AUTOSAR XML (schema 00050)
package /FCASWCs/OnBdDevAb/BufCrk
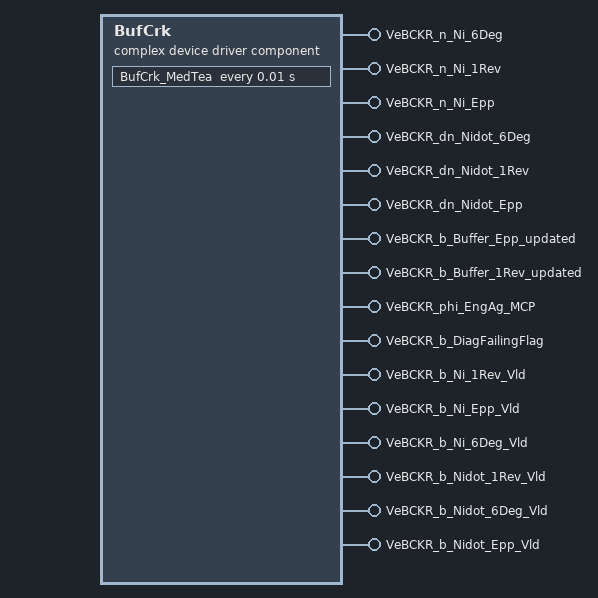
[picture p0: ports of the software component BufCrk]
  complex device driver sw component type BufCrk
    16 x provide port:
      VeBCKR_n_Ni_6Deg: nonqueued-sender-com-spec{data-element=VeBCKR_n_Ni_6Deg, init-value=0}, provided-interface=VeBCKR_n_Ni_6Deg
      VeBCKR_n_Ni_1Rev: nonqueued-sender-com-spec{data-element=VeBCKR_n_Ni_1Rev, init-value=0}, provided-interface=VeBCKR_n_Ni_1Rev
      VeBCKR_n_Ni_Epp: nonqueued-sender-com-spec{data-element=VeBCKR_n_Ni_Epp, init-value=0}, provided-interface=VeBCKR_n_Ni_Epp
      VeBCKR_dn_Nidot_6Deg: nonqueued-sender-com-spec{data-element=VeBCKR_dn_Nidot_6Deg, init-value=0}, provided-interface=VeBCKR_dn_Nidot_6Deg
      VeBCKR_dn_Nidot_1Rev: nonqueued-sender-com-spec{data-element=VeBCKR_dn_Nidot_1Rev, init-value=0}, provided-interface=VeBCKR_dn_Nidot_1Rev
      VeBCKR_dn_Nidot_Epp: nonqueued-sender-com-spec{data-element=VeBCKR_dn_Nidot_Epp, init-value=0}, provided-interface=VeBCKR_dn_Nidot_Epp
      VeBCKR_b_Buffer_Epp_updated: nonqueued-sender-com-spec{data-element=VeBCKR_b_Buffer_Epp_updated, init-value=0}, provided-interface=VeBCKR_b_Buffer_Epp_updated
      VeBCKR_b_Buffer_1Rev_updated: nonqueued-sender-com-spec{data-element=VeBCKR_b_Buffer_1Rev_updated, init-value=0}, provided-interface=VeBCKR_b_Buffer_1Rev_updated
      VeBCKR_phi_EngAg_MCP: nonqueued-sender-com-spec{data-element=VeBCKR_phi_EngAg_MCP, init-value=0}, provided-interface=VeBCKR_phi_EngAg_MCP
      VeBCKR_b_DiagFailingFlag: nonqueued-sender-com-spec{data-element=VeBCKR_b_DiagFailingFlag, init-value=0}, provided-interface=VeBCKR_b_DiagFailingFlag
      VeBCKR_b_Ni_1Rev_Vld: nonqueued-sender-com-spec{data-element=VeBCKR_b_Ni_1Rev_Vld, init-value=0}, provided-interface=VeBCKR_b_Ni_1Rev_Vld
      VeBCKR_b_Ni_Epp_Vld: nonqueued-sender-com-spec{data-element=VeBCKR_b_Ni_Epp_Vld, init-value=0}, provided-interface=VeBCKR_b_Ni_Epp_Vld
      VeBCKR_b_Ni_6Deg_Vld: nonqueued-sender-com-spec{data-element=VeBCKR_b_Ni_6Deg_Vld, init-value=0}, provided-interface=VeBCKR_b_Ni_6Deg_Vld
      VeBCKR_b_Nidot_1Rev_Vld: nonqueued-sender-com-spec{data-element=VeBCKR_b_Nidot_1Rev_Vld, init-value=0}, provided-interface=VeBCKR_b_Nidot_1Rev_Vld
      VeBCKR_b_Nidot_6Deg_Vld: nonqueued-sender-com-spec{data-element=VeBCKR_b_Nidot_6Deg_Vld, init-value=0}, provided-interface=VeBCKR_b_Nidot_6Deg_Vld
      VeBCKR_b_Nidot_Epp_Vld: nonqueued-sender-com-spec{data-element=VeBCKR_b_Nidot_Epp_Vld, init-value=0}, provided-interface=VeBCKR_b_Nidot_Epp_Vld
    behavior IBBufCrk: data-type-mapping=[ADTtoIDTMapping, ADTtoIDTMapping], handle-termination-and-restart=NO-SUPPORT
      timing event MedTea: start-on-event=BufCrk_MedTea, period=0.01  # 10ms update
      runnable BufCrk_MedTea: symbol=BufCrk_BufCrk_MedTea
        data-send-points:
          16 x access:
            DSP_VeBCKR_b_Buffer_1Rev_updated_VeBCKR_b_Buffer_1Rev_updated: accessed-variable=VeBCKR_b_Buffer_1Rev_updated.VeBCKR_b_Buffer_1Rev_updated
            DSP_VeBCKR_b_Buffer_Epp_updated_VeBCKR_b_Buffer_Epp_updated: accessed-variable=VeBCKR_b_Buffer_Epp_updated.VeBCKR_b_Buffer_Epp_updated
            DSP_VeBCKR_b_DiagFailingFlag_VeBCKR_b_DiagFailingFlag: accessed-variable=VeBCKR_b_DiagFailingFlag.VeBCKR_b_DiagFailingFlag
            DSP_VeBCKR_b_Ni_1Rev_Vld_VeBCKR_b_Ni_1Rev_Vld: accessed-variable=VeBCKR_b_Ni_1Rev_Vld.VeBCKR_b_Ni_1Rev_Vld
            DSP_VeBCKR_b_Ni_6Deg_Vld_VeBCKR_b_Ni_6Deg_Vld: accessed-variable=VeBCKR_b_Ni_6Deg_Vld.VeBCKR_b_Ni_6Deg_Vld
            DSP_VeBCKR_b_Ni_Epp_Vld_VeBCKR_b_Ni_Epp_Vld: accessed-variable=VeBCKR_b_Ni_Epp_Vld.VeBCKR_b_Ni_Epp_Vld
            DSP_VeBCKR_b_Nidot_1Rev_Vld_VeBCKR_b_Nidot_1Rev_Vld: accessed-variable=VeBCKR_b_Nidot_1Rev_Vld.VeBCKR_b_Nidot_1Rev_Vld
            DSP_VeBCKR_b_Nidot_6Deg_Vld_VeBCKR_b_Nidot_6Deg_Vld: accessed-variable=VeBCKR_b_Nidot_6Deg_Vld.VeBCKR_b_Nidot_6Deg_Vld
            DSP_VeBCKR_b_Nidot_Epp_Vld_VeBCKR_b_Nidot_Epp_Vld: accessed-variable=VeBCKR_b_Nidot_Epp_Vld.VeBCKR_b_Nidot_Epp_Vld
            DSP_VeBCKR_dn_Nidot_1Rev_VeBCKR_dn_Nidot_1Rev: accessed-variable=VeBCKR_dn_Nidot_1Rev.VeBCKR_dn_Nidot_1Rev
            DSP_VeBCKR_dn_Nidot_6Deg_VeBCKR_dn_Nidot_6Deg: accessed-variable=VeBCKR_dn_Nidot_6Deg.VeBCKR_dn_Nidot_6Deg
            DSP_VeBCKR_dn_Nidot_Epp_VeBCKR_dn_Nidot_Epp: accessed-variable=VeBCKR_dn_Nidot_Epp.VeBCKR_dn_Nidot_Epp
            DSP_VeBCKR_n_Ni_1Rev_VeBCKR_n_Ni_1Rev: accessed-variable=VeBCKR_n_Ni_1Rev.VeBCKR_n_Ni_1Rev
            DSP_VeBCKR_n_Ni_6Deg_VeBCKR_n_Ni_6Deg: accessed-variable=VeBCKR_n_Ni_6Deg.VeBCKR_n_Ni_6Deg
            DSP_VeBCKR_n_Ni_Epp_VeBCKR_n_Ni_Epp: accessed-variable=VeBCKR_n_Ni_Epp.VeBCKR_n_Ni_Epp
            DSP_VeBCKR_phi_EngAg_MCP_VeBCKR_phi_EngAg_MCP: accessed-variable=VeBCKR_phi_EngAg_MCP.VeBCKR_phi_EngAg_MCP
package /FCASWCs/OnBdDevAb/BufCrk/If
  16 x sender receiver interface:
    VeBCKR_b_Buffer_1Rev_updated
      data VeBCKR_b_Buffer_1Rev_updated: type=ADTSBoolean
    VeBCKR_b_Buffer_Epp_updated
      data VeBCKR_b_Buffer_Epp_updated: type=ADTSBoolean
    VeBCKR_b_DiagFailingFlag
      data VeBCKR_b_DiagFailingFlag: type=ADTSBoolean
    VeBCKR_b_Ni_1Rev_Vld  # 6 Degree unfiltered buffered crank speed.
      data VeBCKR_b_Ni_1Rev_Vld: type=ADTSBoolean  # Valid flag for the 6Degree buffered crank
    VeBCKR_b_Ni_6Deg_Vld  # 6 Degree unfiltered buffered crank speed.
      data VeBCKR_b_Ni_6Deg_Vld: type=ADTSBoolean  # Valid flag for the 6Degree buffered crank
    VeBCKR_b_Ni_Epp_Vld  # 6 Degree unfiltered buffered crank speed.
      data VeBCKR_b_Ni_Epp_Vld: type=ADTSBoolean  # Valid flag for the 6Degree buffered crank
    VeBCKR_b_Nidot_1Rev_Vld
      data VeBCKR_b_Nidot_1Rev_Vld: type=ADTSBoolean
    VeBCKR_b_Nidot_6Deg_Vld
      data VeBCKR_b_Nidot_6Deg_Vld: type=ADTSBoolean
    VeBCKR_b_Nidot_Epp_Vld
      data VeBCKR_b_Nidot_Epp_Vld: type=ADTSBoolean
    VeBCKR_dn_Nidot_1Rev
      data VeBCKR_dn_Nidot_1Rev: type=ADTSFloat32_Rpmps
    VeBCKR_dn_Nidot_6Deg
      data VeBCKR_dn_Nidot_6Deg: type=ADTSFloat32_Rpmps
    VeBCKR_dn_Nidot_Epp
      data VeBCKR_dn_Nidot_Epp: type=ADTSFloat32_Rpmps
    VeBCKR_n_Ni_1Rev  # 6 Degree unfiltered buffered crank speed.
      data VeBCKR_n_Ni_1Rev: type=ADTSEngNRpm
    VeBCKR_n_Ni_6Deg  # 6 Degree unfiltered buffered crank speed.
      data VeBCKR_n_Ni_6Deg: type=ADTSEngNRpm
    VeBCKR_n_Ni_Epp  # 6 Degree unfiltered buffered crank speed.
      data VeBCKR_n_Ni_Epp: type=ADTSEngNRpm
    VeBCKR_phi_EngAg_MCP
      data VeBCKR_phi_EngAg_MCP: type=ADTSAbsltEngPosnAgDeg  # Engine Position
